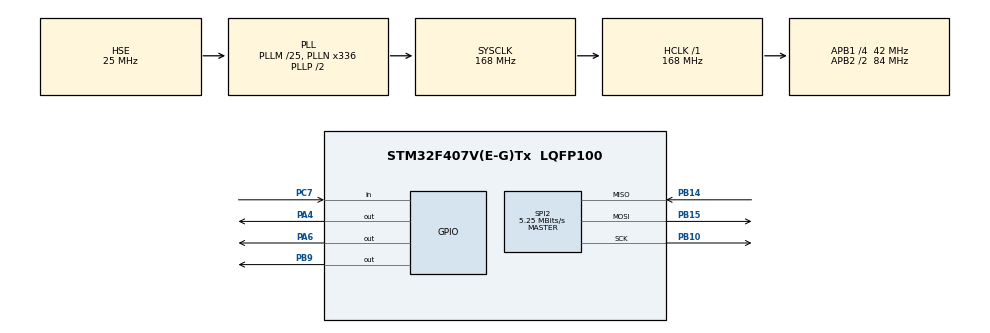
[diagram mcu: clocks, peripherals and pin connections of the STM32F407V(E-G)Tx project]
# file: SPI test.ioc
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Mcu.Family=STM32F4
Mcu.Name=STM32F407V(E-G)Tx
Mcu.Package=LQFP100
NVIC.PriorityGroup=NVIC_PRIORITYGROUP_4
PA4.Signal=GPIO_Output
PA6.Signal=GPIO_Output
PB10.Mode=Full_Duplex_Master
PB10.Signal=SPI2_SCK
PB14.Mode=Full_Duplex_Master
PB14.Signal=SPI2_MISO
PB15.Mode=Full_Duplex_Master
PB15.Signal=SPI2_MOSI
PB9.Signal=GPIO_Output
PC7.Signal=GPIO_Input
PH0-OSC_IN.Mode=HSE-External-Oscillator
PH0-OSC_IN.Signal=RCC_OSC_IN
PH1-OSC_OUT.Mode=HSE-External-Oscillator
PH1-OSC_OUT.Signal=RCC_OSC_OUT
ProjectManager.HeapSize=0x200
ProjectManager.StackSize=0x400
ProjectManager.TargetToolchain=STM32CubeIDE
RCC.48MHZClocksFreq_Value=84000000
RCC.AHBFreq_Value=168000000
RCC.APB1CLKDivider=RCC_HCLK_DIV4
RCC.APB1Freq_Value=42000000
RCC.APB1TimFreq_Value=84000000
RCC.APB2CLKDivider=RCC_HCLK_DIV2
RCC.APB2Freq_Value=84000000
RCC.APB2TimFreq_Value=168000000
RCC.CortexFreq_Value=168000000
RCC.HCLKFreq_Value=168000000
RCC.HSE_VALUE=25000000
RCC.HSI_VALUE=16000000
RCC.LSE_VALUE=32768
RCC.PLLM=25
RCC.PLLN=336
RCC.PLLSourceVirtual=RCC_PLLSOURCE_HSE
RCC.SYSCLKFreq_VALUE=168000000
RCC.SYSCLKSource=RCC_SYSCLKSOURCE_PLLCLK
RCC.VCOOutputFreq_Value=336000000
SPI2.BaudRatePrescaler=SPI_BAUDRATEPRESCALER_8
SPI2.CLKPhase=SPI_PHASE_2EDGE
SPI2.CLKPolarity=SPI_POLARITY_HIGH
SPI2.CalculateBaudRate=5.25 MBits/s
SPI2.Direction=SPI_DIRECTION_2LINES
SPI2.Mode=SPI_MODE_MASTER
SPI2.VirtualType=VM_MASTER
board=custom

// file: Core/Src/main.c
/* USER CODE BEGIN Header */
/**
  ******************************************************************************
  * @file           : main.c
  * @brief          : Main program body
  ******************************************************************************
  * @attention
  *
  * Copyright (c) 2023 STMicroelectronics.
  * All rights reserved.
  *
  * This software is licensed under terms that can be found in the LICENSE file
  * in the root directory of this software component.
  * If no LICENSE file comes with this software, it is provided AS-IS.
  *
  ******************************************************************************
  */
/* USER CODE END Header */
#include "main.h"
#include "spi.h"
#include "gpio.h"

/* USER CODE BEGIN Includes */
#include "VS1003.h"
#include "mp3Sample.h"
#include <stdio.h>
#include <math.h>
/* USER CODE END Includes */

void SystemClock_Config(void);

int main(void)
{

  /* MCU Configuration--------------------------------------------------------*/

  /* Reset of all peripherals, Initializes the Flash interface and the Systick. */
  HAL_Init();

  /* Configure the system clock */
  SystemClock_Config();

  /* Initialize all configured peripherals */
  MX_GPIO_Init();
  MX_SPI2_Init();
  /* USER CODE BEGIN 2 */
  VS1003_Init();
  VS1003_SoftReset();
  /* USER CODE END 2 */

  /* Infinite loop */
  /* USER CODE BEGIN WHILE */
  int i = 0;
  while (1)
  {
	  if(MP3_DREQ == 1){
		  if(sizeof(MP3_DATA) > i) {
			  VS1003_WriteData(&MP3_DATA[i]);
			  i += 32;
		  }
		  else
			  i = 0;
	  }
    /* USER CODE END WHILE */
  }
}

void SystemClock_Config(void)
{
  RCC_OscInitTypeDef RCC_OscInitStruct = {0};
  RCC_ClkInitTypeDef RCC_ClkInitStruct = {0};

  /** Configure the main internal regulator output voltage
  */
  __HAL_RCC_PWR_CLK_ENABLE();
  __HAL_PWR_VOLTAGESCALING_CONFIG(PWR_REGULATOR_VOLTAGE_SCALE1);

  /** Initializes the RCC Oscillators according to the specified parameters
  * in the RCC_OscInitTypeDef structure.
  */
  RCC_OscInitStruct.OscillatorType = RCC_OSCILLATORTYPE_HSE;
  RCC_OscInitStruct.HSEState = RCC_HSE_ON;
  RCC_OscInitStruct.PLL.PLLState = RCC_PLL_ON;
  RCC_OscInitStruct.PLL.PLLSource = RCC_PLLSOURCE_HSE;
  RCC_OscInitStruct.PLL.PLLM = 25;
  RCC_OscInitStruct.PLL.PLLN = 336;
  RCC_OscInitStruct.PLL.PLLP = RCC_PLLP_DIV2;
  RCC_OscInitStruct.PLL.PLLQ = 4;
  if (HAL_RCC_OscConfig(&RCC_OscInitStruct) != HAL_OK)
  {
    Error_Handler();
  }

  /** Initializes the CPU, AHB and APB buses clocks
  */
  RCC_ClkInitStruct.ClockType = RCC_CLOCKTYPE_HCLK|RCC_CLOCKTYPE_SYSCLK
                              |RCC_CLOCKTYPE_PCLK1|RCC_CLOCKTYPE_PCLK2;
  RCC_ClkInitStruct.SYSCLKSource = RCC_SYSCLKSOURCE_PLLCLK;
  RCC_ClkInitStruct.AHBCLKDivider = RCC_SYSCLK_DIV1;
  RCC_ClkInitStruct.APB1CLKDivider = RCC_HCLK_DIV4;
  RCC_ClkInitStruct.APB2CLKDivider = RCC_HCLK_DIV2;

  if (HAL_RCC_ClockConfig(&RCC_ClkInitStruct, FLASH_LATENCY_5) != HAL_OK)
  {
    Error_Handler();
  }
}

void Error_Handler(void)
{
  __disable_irq();
  while (1)
  {
  }
}
